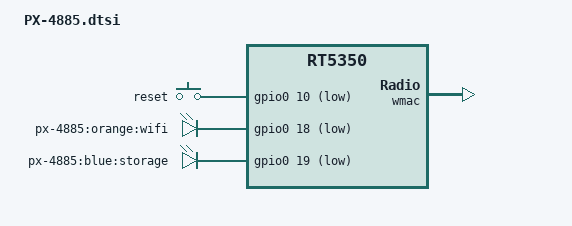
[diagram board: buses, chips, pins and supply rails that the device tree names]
#include "rt5350.dtsi"

#include <dt-bindings/gpio/gpio.h>
#include <dt-bindings/input/input.h>

/ {
	compatible = "7links,px-4885", "ralink,rt5350-soc";

	aliases {
		led-status = &led_wifi;
	};

	gpio-keys-polled {
		compatible = "gpio-keys-polled";
		poll-interval = <20>;

		reset {
			label = "reset";
			gpios = <&gpio0 10 GPIO_ACTIVE_LOW>;
			linux,code = <KEY_RESTART>;
		};
	};

	gpio-leds {
		compatible = "gpio-leds";

		led_wifi: wifi {
			label = "px-4885:orange:wifi";
			gpios = <&gpio0 18 GPIO_ACTIVE_LOW>;
		};

		storage {
			label = "px-4885:blue:storage";
			gpios = <&gpio0 19 GPIO_ACTIVE_LOW>;
		};
	};
};

&pinctrl {
	state_default: pinctrl0 {
		gpio {
			ralink,group = "i2c", "jtag", "uartf";
			ralink,function = "gpio";
		};
	};
};

&ethernet {
	mtd-mac-address = <&factory 0x28>;
};

&esw {
	mediatek,portmap = <0x3f>;
};

&wmac {
	ralink,mtd-eeprom = <&factory 0>;
};
